# target register map
Vendor: Vango; Series: TARGET; File version: 1.0
Vango 32-bit Cortex-M0 Microcontroller based device, CPU clock up to 26 MHz.
CPU: CM0 r0p0, little endian, no MPU, no FPU, 2 interrupt priority bits
Registers are 32-bit, read-write, reset 0x0 unless marked. A register's access mark holds for its fields unless they carry their own. Offsets are from the block's base; lines under a group give offsets from that group; [hi:lo] are bit positions; {n}, {i} and the like mark numbered series; 'fields as' and 'values as' point back to an identical list; <NAME> marks a mode.

## Memory map
0x000FFF00 FLASH size 0x100
0x40000020 GPIOB size 0x20 — The GPIO controller is used to control the GPIOs of TARGET.
0x40000040 GPIOC size 0x20 — The GPIO controller is used to control the GPIOs of TARGET.
0x40000060 GPIOD size 0x20 — The GPIO controller is used to control the GPIOs of TARGET.
0x40000080 GPIOE size 0x20 — The GPIO controller is used to control the GPIOs of TARGET.
0x400000A0 GPIOF size 0x20 — The GPIO controller is used to control the GPIOs of TARGET.
0x400000C0 GPIOAF size 0x24 — The GPIO controller is used to control the GPIOs of TARGET.
0x40002000 LCD size 0x120 — The LCD controller is used to display content on the LCD panel.
0x40006000 CRYPT size 0x14 — CRYPT accelerate the sign and verify process speed of ECC.
0x40010000 DMA size 0x80 — DMA(Direct Memory Access)
0x40010800 I2C size 0x1C — I2C-Inter Integrated Circuit
0x40011000 SPI1 size 0x18 — SPI(Serial Peripheral Interface).
0x40011800 UART0 size 0x18 — UART(Universal Asynchronous Receiver/Transmitter).
0x40011820 UART1 size 0x18
0x40011840 UART2 size 0x18
0x40011860 UART3 size 0x18
0x40011880 UART4 size 0x18
0x400118A0 UART5 size 0x18
0x40012000 ISO78160 size 0x20 — The ISO7816 controller is an enhance UART protocol which is able to do half-duplex communication on the 2 wires bus.
0x40012040 ISO78161 size 0x20
0x40012800 TMR0 size 0x20 — General purpose 32 bits timer, which are used to generate regulate interrupt for CM0.
0x40012820 TMR1 size 0x20
0x40012840 TMR2 size 0x20
0x40012860 TMR3 size 0x20
0x40012900 PWM0 size 0x20 — Timers are 16 bits timers with PWM and capture function.
0x40012920 PWM1 size 0x20
0x40012940 PWM2 size 0x20
0x40012960 PWM3 size 0x20
0x400129F0 PWM_SEL size 0xC — Timers are 16 bits timers with PWM and capture function.
0x40013000 MISC1 size 0x28 — The MISC controller is used to control some special function of TARGET, which will be power-off during sleep and deep-sleep mode.
0x40013E00 MISC2 size 0x18 — MISC2 controller is in retention domain which will be power-off at deep-sleep mode.
0x40014000 PMU size 0x500 — Power Management Unit.
0x40014010 GPIOA size 0x44 — The GPIO controller is used to control the GPIOs of TARGET.
0x40014100 U32K0 size 0x14 — The UART 32K controller is used to receive data via UART protocol.
0x40014180 U32K1 size 0x14
0x40014200 ANA size 0x100 — The Analog controller is used to control the analog function of TARGET.
0x40014800 RTC size 0x200 — The RTC controller is used to control time calculation and RTC auto calibration function.
0x40015800 SPI2 size 0x18
0x40016000 SPI3 size 0x18

## Interrupts
0 PMU
1 RTC
2 U32K0
3 U32K1
4 I2C
5 SPI1
6 UART0
7 UART1
8 UART2
9 UART3
10 UART4
11 UART5
12 ISO78160
13 ISO78161
14 TMR0
15 TMR1
16 TMR2
17 TMR3
18 PWM0
19 PWM1
20 PWM2
21 PWM3
22 DMA
23 FLASH
24 ANA
27 SPI2
28 SPI3

## CRYPT — CRYPT accelerate the sign and verify process speed of ECC.
Base 0x40006000
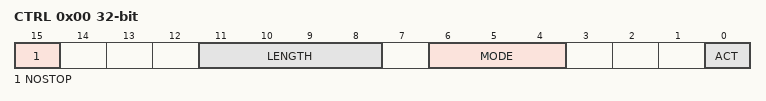
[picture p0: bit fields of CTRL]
0x00 CTRL — CRYPT control register.
  [15] NOSTOP — This register is used to control if the cpu will be stop by CRYPT engine when the CRYPT engine is busy and CPU read or write CRPYT engine register.
  [11:8] LENGTH — This bit is used to control the VLI length of current operation.
  [6:4] MODE — This trgister controls the operation mode of crypt engine .
    0=Multiply_mode; 1=Add_mode; 2=Sub_mode; 3=RSHIFT1_mode
  [0] ACT — Write 1 to this bit will start an operation specified in the MODE register.
0x04 PTRA — CRYPT pointer A.
  [15:0] PTRA — This is the PTRA register of CRYPT controller.
0x08 PTRB — CRYPT pointer B.
  [15:0] PTRB — This is the PTRB register of CRYPT controller.
0x0C PTRO — CRYPT pointer O.
  [15:0] PTRO — This is the PTRO register of CRYPT controller.
0x10 CARRY read — CRYPT carry/borrow bit register.
  [0] CARRY — This bit represent the carry bit after add operation is done. The bit represent borrow bit after sub operation is done. Programmer can read this register immediately after the ACT bit is set to 1.
